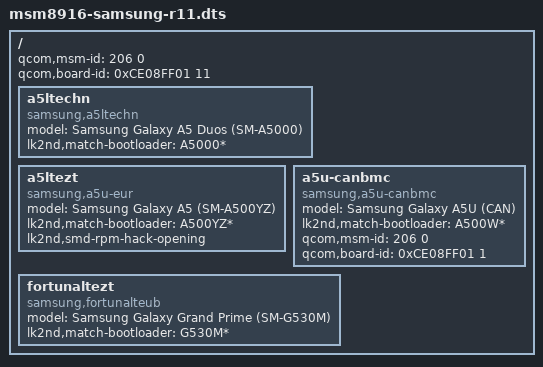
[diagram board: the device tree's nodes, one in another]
// SPDX-License-Identifier: GPL-2.0-only

/dts-v1/;

#include <skeleton.dtsi>
#include <lk2nd.h>

/ {
	// This is used by the bootloader to find the correct DTB
	qcom,msm-id = <206 0>;
	qcom,board-id = <0xCE08FF01 11>;
	
	// In downstream it is called Samsung A5 PROJECT Rev11 and its marketing name is Samsung Galaxy A5 Duos
	a5ltechn {
		model = "Samsung Galaxy A5 Duos (SM-A5000)";
		compatible = "samsung,a5ltechn", "qcom,msm8916", "lk2nd,device";
		lk2nd,match-bootloader = "A5000*";
	};

	a5ltezt {
		model = "Samsung Galaxy A5 (SM-A500YZ)";
		compatible = "samsung,a5u-eur", "qcom,msm8916", "lk2nd,device";
		lk2nd,match-bootloader = "A500YZ*";
		lk2nd,smd-rpm-hack-opening;
	};
	
	a5u-canbmc {
		// In downstream it is called Samsung A5U CAN PROJECT Rev01
		model = "Samsung Galaxy A5U (CAN)";
		compatible = "samsung,a5u-canbmc", "qcom,msm8916", "lk2nd,device";
		lk2nd,match-bootloader = "A500W*";
		qcom,msm-id = <206 0>;
		qcom,board-id = <0xCE08FF01 1>;
	};

	/*
	 * Before building for G530Y, please comment out all dtbs except
	 * "$(LOCAL_DIR)/msm8916-samsung-r11.dtb" at './rules.mk'.
	 * fortunaltezt doesn't work with multi-dtbs; only goes into "Download mode".
	 */
	fortunaltezt {
		model = "Samsung Galaxy Grand Prime (SM-G530Y)";
		compatible = "samsung,fortunaltezt", "qcom,msm8916", "lk2nd,device";
		lk2nd,match-bootloader = "G530Y*";
		#include "msm8916-samsung-gprime.dtsi"
	};

	/*
	 * Before building for G530Y, please comment out all dtbs except
	 * "$(LOCAL_DIR)/msm8916-samsung-r11.dtb" at './rules.mk'.
	 * fortunaltezt doesn't work with multi-dtbs; only goes into "Download mode".
	 */
	fortunaltezt {
		model = "Samsung Galaxy Grand Prime (SM-G530M)";
		compatible = "samsung,fortunalteub", "qcom,msm8916", "lk2nd,device";
		lk2nd,match-bootloader = "G530M*";
		#include "msm8916-samsung-gprime.dtsi"
	};
};
